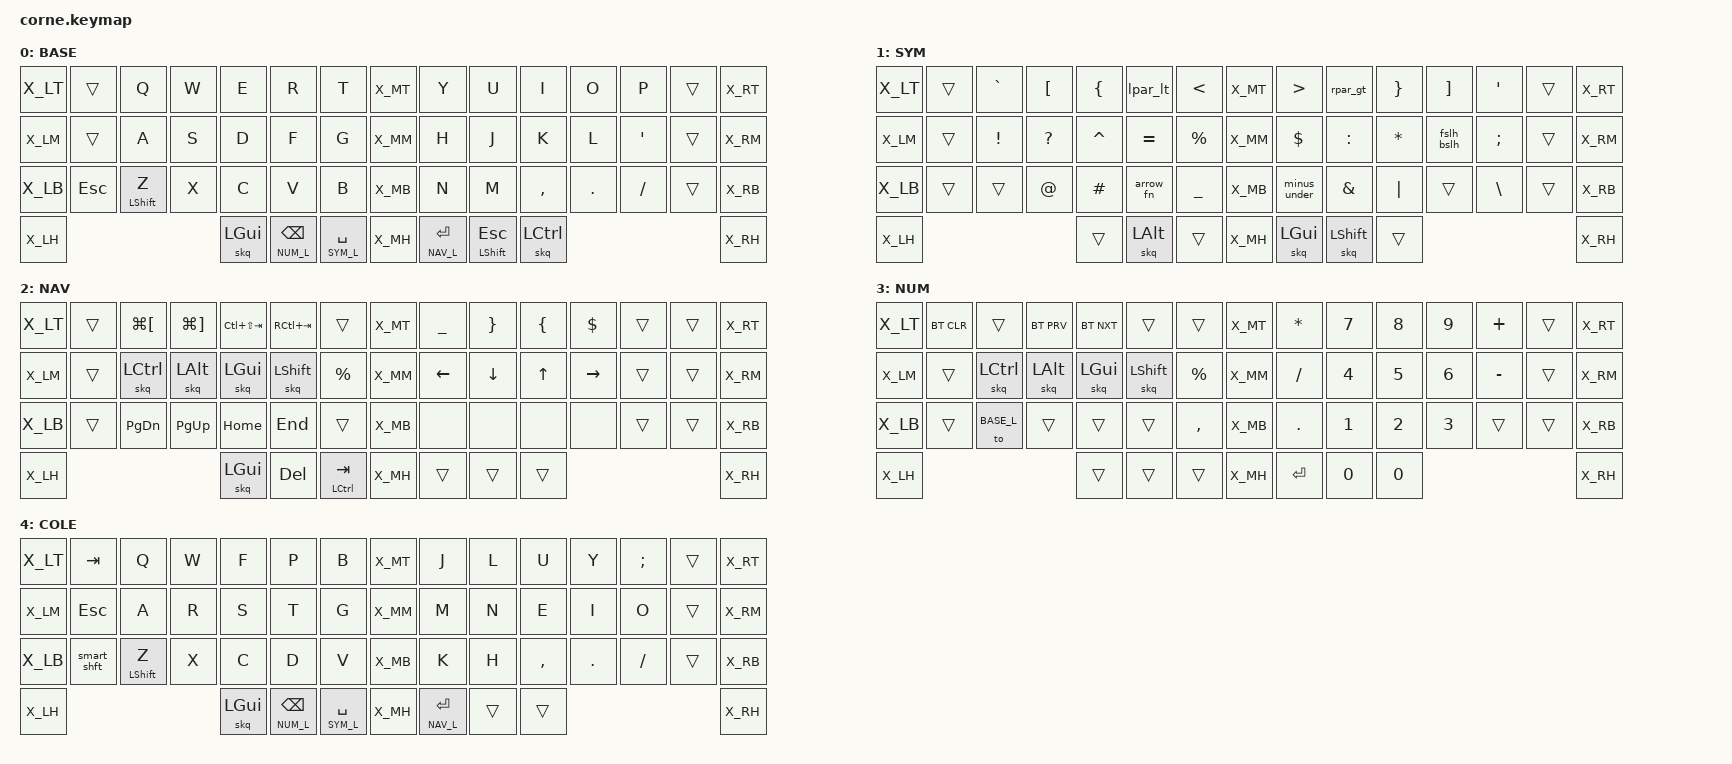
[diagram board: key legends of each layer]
/*
 * Copyright (c) 2020 The ZMK Contributors
 *
 * SPDX-License-Identifier: MIT
 */

#include <behaviors.dtsi>
#include <dt-bindings/zmk/keys.h>
#include <dt-bindings/zmk/bt.h>

#include "../zmk-nodefree-config/helper.h"

#define BASE_L 0
#define SYM_L 1
#define NAV_L 2
#define NUM_L 3
#define COLE_L 4

// #include "combos.dtsi"  // requires layer aliases
// #include "mouse.dtsi"
#include "extra_keys.h"

#define XXX &none
#define ___ &trans

/* Global settings */

#define QUICK_TAP_MS 175
#define TAP_TERM_MS 200

&lt {  // layer-tap config
    flavor = "balanced";
    tapping-term-ms = <TAP_TERM_MS>;
    quick-tap-ms = <QUICK_TAP_MS>;
};

&mt { // mod-tap config
    flavor = "tap-preferred";
    tapping-term-ms = <TAP_TERM_MS>;
};

// sticky quick release
ZMK_BEHAVIOR(skq, sticky_key,
    release-after-ms = <1000>;
    bindings = <&kp>;
    quick-release;
    ignore-modifiers;
)

/* Caps-word, num-word and smart-mouse */
// tap: sticky-shift | shift + tap/double-tap: caps-word | hold: shift
ZMK_BEHAVIOR(smart_shft, mod_morph,
    bindings = <&sk LSHFT>, <&caps_word>;
    mods = <(MOD_LSFT)>;
)
&caps_word {  // mods deactivate caps-word, requires PR #1441
    /delete-property/ ignore-modifiers;
};

// tap: num-word | double-tap: sticky num-layer | hold: num-layer
#define SMART_NUM &smart_num NUM_L BASE_L
ZMK_BEHAVIOR(smart_num, hold_tap,
    flavor = "balanced";
    tapping-term-ms = <200>;
    quick-tap-ms = <QUICK_TAP_MS>;
    bindings = <&mo>, <&num_dance>;
)
ZMK_BEHAVIOR(num_dance, tap_dance,
    tapping-term-ms = <200>;
    bindings = <&num_word>, <&sl NUM_L>;  // reverse this for sticky-num on single tap
)
&num_word {  // num-word, requires PR #1441
    layers = <NUM_L>;
    continue-list = <BSPC DEL DOT COMMA PLUS MINUS STAR FSLH EQUAL>;
};

// tap: comma | shift + tap: semicolon | ctrl + shift + tap: <
ZMK_BEHAVIOR(comma_morph, mod_morph,
    mods = <(MOD_LSFT|MOD_RSFT)>;
    bindings = <&kp COMMA>, <&comma_inner_morph>;
)
ZMK_BEHAVIOR(comma_inner_morph, mod_morph,
    bindings = <&kp SEMICOLON>, <&kp LESS_THAN>;
    mods = <(MOD_LCTL|MOD_RCTL)>;
)

// tap: dot | shift + tap: colon | ctrl + shift + tap: >
ZMK_BEHAVIOR(dot_morph, mod_morph,
    bindings = <&kp DOT>, <&dot_inner_morph>;
    mods = <(MOD_LSFT|MOD_RSFT)>;
)
ZMK_BEHAVIOR(dot_inner_morph, mod_morph,
    bindings = <&kp COLON>, <&kp GREATER_THAN>;
    mods = <(MOD_LCTL|MOD_RCTL)>;
)

// tap: left-parenthesis | shft + tap: less-than
ZMK_BEHAVIOR(lpar_lt, mod_morph,
    bindings = <&kp LPAR>, <&kp LT>;
    mods = <(MOD_LSFT|MOD_RSFT)>;
)

// tap: right-parenthesis | shft + tap: greater-than
ZMK_BEHAVIOR(rpar_gt, mod_morph,
    bindings = <&kp RPAR>, <&kp GT>;
    mods = <(MOD_LSFT|MOD_RSFT)>;
)

// tap: back slash | shft + tap: forward slash
ZMK_BEHAVIOR(fslh_bslh, mod_morph,
    bindings = <&kp FSLH>, <&kp BSLH>;
    mods = <(MOD_LSFT|MOD_RSFT)>;
)

// tap: minus | shft + tap: underscore
ZMK_BEHAVIOR(minus_under, mod_morph,
    bindings = <&kp MINUS>, <&kp UNDER>;
    mods = <(MOD_LSFT|MOD_RSFT)>;
)

/* coding */
ZMK_BEHAVIOR(three_eq, macro,
    bindings = <&macro_tap &kp EQUAL>, <&macro_tap &kp EQUAL>, <&macro_tap &kp EQUAL>;
)
ZMK_BEHAVIOR(up_dir, macro,
    bindings = <&macro_tap &kp DOT>, <&macro_tap &kp DOT>, <&macro_tap &kp FSLH>;
)
ZMK_BEHAVIOR(arrow_fn, macro,
    bindings = <&macro_tap &kp EQUAL>, <&macro_tap &kp GT>;
)

ZMK_LAYER(BASE,
    //╭──────╮ ╭─────────────┬─────────────┬─────────────┬─────────────┬─────────────┬─────────────╮ ╭──────╮ ╭─────────────┬─────────────┬─────────────┬─────────────┬─────────────┬─────────────╮ ╭──────╮
        X_LT     ___           &kp Q         &kp W         &kp E         &kp R         &kp T           X_MT     &kp Y         &kp U         &kp I         &kp O         &kp P         ___             X_RT
    //├──────┤ ├─────────────┼─────────────┼─────────────┼─────────────┼─────────────┼─────────────┤ ├──────┤ ├─────────────┼─────────────┼─────────────┼─────────────┼─────────────┼─────────────┤ ├──────┤
        X_LM     ___           &kp A         &kp S         &kp D         &kp F         &kp G           X_MM     &kp H         &kp J         &kp K         &kp L         &kp SQT       ___             X_RM
    //├──────┤ ├─────────────┼─────────────┼─────────────┼─────────────┼─────────────┼─────────────┤ ├──────┤ ├─────────────┼─────────────┼─────────────┼─────────────┼─────────────┼─────────────┤ ├──────┤
        X_LB     &kp ESC       &mt LSHFT Z   &kp X         &kp C         &kp V         &kp B           X_MB     &kp N         &kp M         &kp COMMA     &kp DOT       &kp FSLH      ___             X_RB
    //├──────┤ ╰─────────────┴─────────────┴─────────────┼─────────────┼─────────────┼─────────────┤ ├──────┤ ├─────────────┼─────────────┼─────────────┴─────────────┴─────────────┴─────────────╯ ├──────┤
        X_LH                                               &skq LGUI     &lt NUM_L BSPC &lt SYM_L SPACE X_MH    &lt NAV_L RET &mt LSHFT ESC &skq LCTRL                                                X_RH
    //╰──────╯                                           ╰─────────────┴─────────────┴─────────────╯ ╰──────╯ ╰─────────────┴─────────────┴─────────────╯                                           ╰──────╯
)

ZMK_LAYER(SYM,
    //╭──────╮ ╭─────────────┬─────────────┬─────────────┬─────────────┬─────────────┬─────────────╮ ╭──────╮ ╭─────────────┬─────────────┬─────────────┬─────────────┬─────────────┬─────────────╮ ╭──────╮
        X_LT     ___           &kp GRAVE     &kp LBKT      &kp LBRC      &lpar_lt      &kp LT          X_MT     &kp GT        &rpar_gt      &kp RBRC      &kp RBKT      &kp SQT      ___             X_RT
    //├──────┤ ├─────────────┼─────────────┼─────────────┼─────────────┼─────────────┼─────────────┤ ├──────┤ ├─────────────┼─────────────┼─────────────┼─────────────┼─────────────┼─────────────┤ ├──────┤
        X_LM     ___           &kp EXCL      &kp QMARK     &kp CARET     &kp EQUAL     &kp PRCNT       X_MM     &kp DLLR      &kp COLON     &kp STAR      &fslh_bslh    &kp SEMI      ___             X_RM
    //├──────┤ ├─────────────┼─────────────┼─────────────┼─────────────┼─────────────┼─────────────┤ ├──────┤ ├─────────────┼─────────────┼─────────────┼─────────────┼─────────────┼─────────────┤ ├──────┤
        X_LB     ___           ___           &kp AT        &kp HASH      &arrow_fn     &kp UNDER       X_MB     &minus_under  &kp AMPS      &kp PIPE      ___           &kp BSLH      ___             X_RB
    //├──────┤ ╰─────────────┴─────────────┴─────────────┼─────────────┼─────────────┼─────────────┤ ├──────┤ ├─────────────┼─────────────┼─────────────┴─────────────┴─────────────┴─────────────╯ ├──────┤
        X_LH                                               ___           &skq LALT     ___             X_MH     &skq LGUI     &skq LSHFT    ___                                                       X_RH
    //╰──────╯                                           ╰─────────────┴─────────────┴─────────────╯ ╰──────╯ ╰─────────────┴─────────────┴─────────────╯                                           ╰──────╯
)

ZMK_LAYER(NAV,
    //╭──────╮ ╭─────────────┬─────────────┬─────────────┬─────────────┬─────────────┬─────────────╮ ╭──────╮ ╭─────────────┬─────────────┬─────────────┬─────────────┬─────────────┬─────────────╮ ╭──────╮
        X_LT     ___           &kp LG(LBKT)  &kp LG(RBKT)  &kp LC(LS(TAB)) &kp RC(TAB) ___             X_MT     &kp UNDER     &kp RBRC      &kp LBRC      &kp DLLR      ___           ___             X_RT
    //├──────┤ ├─────────────┼─────────────┼─────────────┼─────────────┼─────────────┼─────────────┤ ├──────┤ ├─────────────┼─────────────┼─────────────┼─────────────┼─────────────┼─────────────┤ ├──────┤
        X_LM     ___           &skq LCTRL    &skq LALT     &skq LGUI     &skq LSHFT    &kp PRCNT       X_MM     &kp LEFT      &kp DOWN      &kp UP        &kp RIGHT     ___           ___             X_RM
    //├──────┤ ├─────────────┼─────────────┼─────────────┼─────────────┼─────────────┼─────────────┤ ├──────┤ ├─────────────┼─────────────┼─────────────┼─────────────┼─────────────┼─────────────┤ ├──────┤
        X_LB     ___           &kp PG_DN     &kp PG_UP     &kp HOME      &kp END       ___             X_MB     XXX           XXX           XXX           XXX          ___           ___              X_RB
    //├──────┤ ╰─────────────┴─────────────┴─────────────┼─────────────┼─────────────┼─────────────┤ ├──────┤ ├─────────────┼─────────────┼─────────────┴─────────────┴─────────────┴─────────────╯ ├──────┤
        X_LH                                               &skq LGUI     &kp DEL       &mt LCTRL TAB   X_MH     ___           ___           ___                                                       X_RH
    //╰──────╯                                           ╰─────────────┴─────────────┴─────────────╯ ╰──────╯ ╰─────────────┴─────────────┴─────────────╯                                           ╰──────╯
)

ZMK_LAYER(NUM,
    //╭──────╮ ╭─────────────┬─────────────┬─────────────┬─────────────┬─────────────┬─────────────╮ ╭──────╮ ╭─────────────┬─────────────┬─────────────┬─────────────┬─────────────┬─────────────╮ ╭──────╮
        X_LT     &bt BT_CLR    ___           &bt BT_PRV    &bt BT_NXT    ___           ___             X_MT     &kp STAR      &kp N7        &kp N8        &kp N9        &kp PLUS     ___              X_RT
    //├──────┤ ├─────────────┼─────────────┼─────────────┼─────────────┼─────────────┼─────────────┤ ├──────┤ ├─────────────┼─────────────┼─────────────┼─────────────┼─────────────┼─────────────┤ ├──────┤
        X_LM     ___           &skq LCTRL    &skq LALT     &skq LGUI     &skq LSHFT    &kp PRCNT       X_MM     &kp FSLH      &kp N4        &kp N5        &kp N6        &kp MINUS      ___            X_RM
    //├──────┤ ├─────────────┼─────────────┼─────────────┼─────────────┼─────────────┼─────────────┤ ├──────┤ ├─────────────┼─────────────┼─────────────┼─────────────┼─────────────┼─────────────┤ ├──────┤
        X_LB     ___           &to BASE_L    ___           ___           ___           &kp COMMA       X_MB     &kp DOT       &kp N1        &kp N2        &kp N3        ___           ___             X_RB
    //├──────┤ ╰─────────────┴─────────────┴─────────────┼─────────────┼─────────────┼─────────────┤ ├──────┤ ├─────────────┼─────────────┼─────────────┴─────────────┴─────────────┴─────────────╯ ├──────┤
        X_LH                                               ___           ___           ___             X_MH     &kp RET       &kp N0        &kp N0                                                    X_RH
    //╰──────╯                                           ╰─────────────┴─────────────┴─────────────╯ ╰──────╯ ╰─────────────┴─────────────┴─────────────╯                                           ╰──────╯
)

ZMK_LAYER(COLE,
    //╭──────╮ ╭─────────────┬─────────────┬─────────────┬─────────────┬─────────────┬─────────────╮ ╭──────╮ ╭─────────────┬─────────────┬─────────────┬─────────────┬─────────────┬─────────────╮ ╭──────╮
        X_LT     &kp TAB       &kp Q         &kp W         &kp F         &kp P         &kp B           X_MT     &kp J         &kp L         &kp U         &kp Y         &kp SEMI      ___             X_RT
    //├──────┤ ├─────────────┼─────────────┼─────────────┼─────────────┼─────────────┼─────────────┤ ├──────┤ ├─────────────┼─────────────┼─────────────┼─────────────┼─────────────┼─────────────┤ ├──────┤
        X_LM     &kp ESC       &kp A         &kp R         &kp S         &kp T         &kp G           X_MM     &kp M         &kp N         &kp E         &kp I         &kp O         ___             X_RM
    //├──────┤ ├─────────────┼─────────────┼─────────────┼─────────────┼─────────────┼─────────────┤ ├──────┤ ├─────────────┼─────────────┼─────────────┼─────────────┼─────────────┼─────────────┤ ├──────┤
        X_LB     &smart_shft   &mt LSHFT Z   &kp X         &kp C         &kp D         &kp V           X_MB     &kp K         &kp H         &kp COMMA     &kp DOT       &kp FSLH      ___             X_RB
    //├──────┤ ╰─────────────┴─────────────┴─────────────┼─────────────┼─────────────┼─────────────┤ ├──────┤ ├─────────────┼─────────────┼─────────────┴─────────────┴─────────────┴─────────────╯ ├──────┤
        X_LH                                               &skq LGUI     &lt NUM_L BSPC &lt SYM_L SPACE X_MH    &lt NAV_L RET ___           ___                                                       X_RH
    //╰──────╯                                           ╰─────────────┴─────────────┴─────────────╯ ╰──────╯ ╰─────────────┴─────────────┴─────────────╯                                           ╰──────╯
)
